# myChip register map
Vendor: ARM Ltd.; Series: ARMCM3; File version: 1.2
CPU: CM3 r2p1, little endian, no MPU, no FPU, 3 interrupt priority bits
Registers are 32-bit, read-write, reset 0x0 unless marked. A register's access mark holds for its fields unless they carry their own. Offsets are from the block's base; [hi:lo] are bit positions; {n}, {i} and the like mark numbered series.

## TMR9
Base 0x40030000
Same registers: TMR10 0x40031000
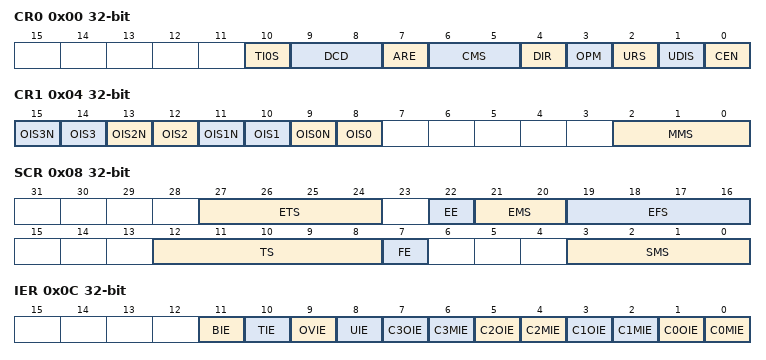
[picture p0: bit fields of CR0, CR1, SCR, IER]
0x00 CR0 — TMRx Control Register0
  [10] TI0S — TI0输入选择(TI0 Input Selection)
  [9:8] DCD — 时钟分频(Clock Division)
  [7] ARE — 自动重载使能(AutoReload Enable)
  [6:5] CMS — 中心对齐模式(Center-Aligned Mode Selection)
  [4] DIR — 计数方向(Counter Direction)
  [3] OPM — 单脉冲模式(One Pulse Mode)
  [2] URS — 更新事件源(Update Request Source)
  [1] UDIS — 更新禁止位(Update Disable)
  [0] CEN — 计数器使能位(Counter Enable):
0x04 CR1 — TMRx Control Register1
  [2n+9] OIS{n}N (n=0..3) — CH{n}N空闲状态输出电平(CH{n}N Output Idle-State):
  [2n+8] OIS{n} (n=0..3) — CH{n}空闲状态输出电平(CH{n} Output Idle-State):
  [2:0] MMS — 主模式选择(Master Mode Selection):
0x08 SCR — TMRx Slave Control Register
  [27:24] ETS — ETR输入源选择(ETR Input Shource Selection)
  [22] EE — ETR控制模式选择(ETR Mode Selection)
  [21:20] EMS — ETR边沿模式选择(ETR Edge-Mode Selection)
  [19:16] EFS — ETR滤波选择(ETR Filter Selection)
  [12:8] TS — 触发选择(Trigger Selection)
  [7] FE — 主从快速同步使能(Master/Slave Fast-Sync Enable)
  [3:0] SMS — 从模式选择(Slave Mode Selection):
0x0C IER — TMRx Interrupt Enable Register
  [11] BIE — 断路中断使能(Break Interrupt Enable)
  [10] TIE — 触发中断使能(Trigger Interrupt Enable)
  [9] OVIE — 计数上溢中断使能(Overflow Interrupt Enable)
  [8] UIE — 更新中断使能(Update Interrupt Enable)
  [2n+1] C{n}OIE (n=0..3) — CH{n}重复捕获中断使能(CH{n} OverCapture Interrupt Enable):
  [2n] C{n}MIE (n=0..3) — CH{n}比较中断使能(CH{n} Capture/Compare Interrupt Enable):
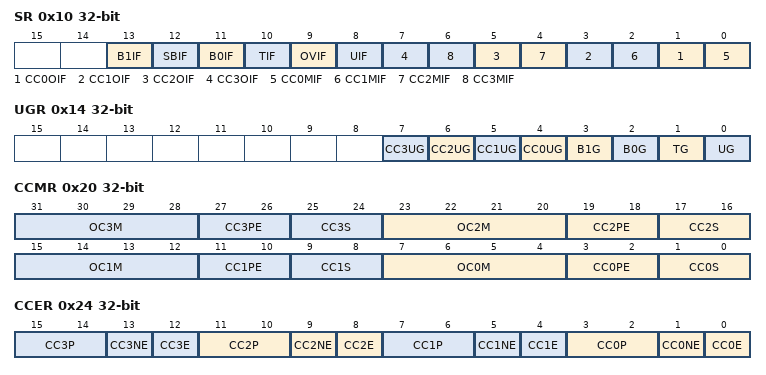
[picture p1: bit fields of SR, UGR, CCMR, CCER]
0x10 SR — TMRx Status Register
  [13] B1IF — 断路中断标志位(Break1 Interrupt Flag)
  [12] SBIF — 系统断路中断标志位(System Fault Break Interrupt Flag)
  [11] B0IF — 断路中断标志位(Break0 Interrupt Flag)
  [10] TIF — 触发中断标志(Trigger Interrupt Flag)
  [9] OVIF — 计数器上溢中断标志位(Counter Overflow Interrupt Flag)
  [8] UIF — 更新中断标志(Update Interrupt Flag)
  [2n+1] CC{n}OIF (n=0..3) — CC{n}重复捕获成功中断标志位(CC{n} OverCapture Interrupt Flag)
  [2n] CC{n}MIF (n=0..3) — CC{n}比较成功中断标志位(CC{n} Capture/Compare Interrupt Flag)
0x14 UGR — TMRx Update Generation Register
  [n+4] CC{n}UG (n=0..3) — CC{n}捕获/比较更新事件生成(CC{n} Capture/Compare Update Generation)
  [3] B1G — 断路1事件生成(Break1 Generation)
  [2] B0G — 断路0事件生成(Break0 Generation)
  [1] TG — 触发事件生成(Trigger Generation)
  [0] UG — 更新事件生成(Update Generation)
0x20 CCMR — TMRx Capture Compare Mode Register
  [8n+7:8n+4] OC{n}M (n=0..3) — CC{n}输入滤波/输出比较模式选择(CC{n} Input Filter/Output Compare Mode)
  [8n+3:8n+2] CC{n}PE (n=0..3) — CC{n}输入捕获分频/比较自动加载使能(CC{n} Compare Auto-Realod Enable)
  [8n+1:8n] CC{n}S (n=0..3) — CC{n}捕获/比较方向选择(CC{n} Capture Compare Selection)
0x24 CCER — TMRx Capture Compare Enable Register
  [4n+3:4n+2] CC{n}P (n=0..3) — CC{n}捕获/比较极性选择(CC{n} Compare/Capture Polarity)
  [4n+1] CC{n}NE (n=0..3) — CC{n}N捕获/比较互补通道使能(CC{n}N Capture/Compare Enable)
  [4n] CC{n}E (n=0..3) — CC{n}捕获/比较通道使能(CC{n} Capture/Compare Enable)
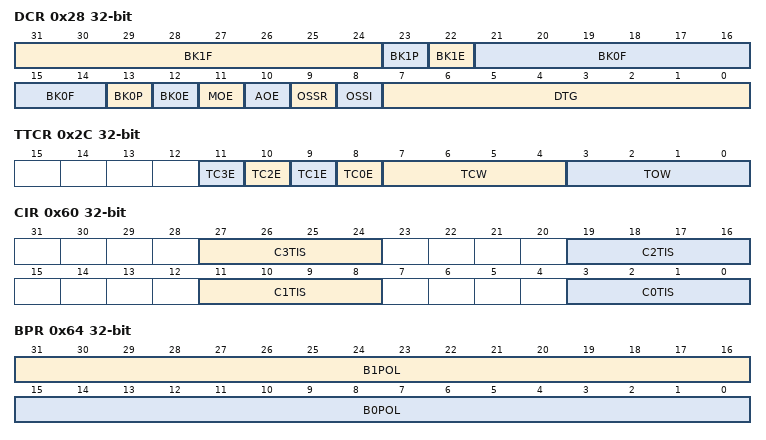
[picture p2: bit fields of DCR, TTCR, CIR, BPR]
0x28 DCR — TMRx Dead-Time Contorl Register
  [31:24] BK1F — 断路滤波器(Break1 Filter)
  [23] BK1P — 断路输入极性(Break1 Polarity)
  [22] BK1E — 断路控制使能(Break1 Enable)
  [21:14] BK0F — 断路滤波器(Break0 Filter)
  [13] BK0P — 断路输入极性(Break0 Polarity)
  [12] BK0E — 断路控制使能(Break0 Enable)
  [11] MOE — 主路输出使能(Main Output Enable)
  [10] AOE — 自动输出使能(Automatic Output Enable)
  [9] OSSR — 运行模式下关闭状态选择(Off-State Selection for Run-Mode)
  [8] OSSI — 空闲模式下关闭状态选择(Off-State Selection for Idle-Mode)
  [7:0] DTG — 配置死区时间选择(Dead-Time Generator Setup)
0x2C TTCR — TMRx Trigger Cycles Register
  [n+8] TC{n}E (n=0..3) — TRGO CH{n}输出使能(Trigger CH{n} Enable)
  [7:4] TCW — TRGCC脉冲宽度控制(Trigger Compare/Caputre Width)
  [3:0] TOW — TRGO脉冲宽度控制(Trigger Output Width)
0x30 CPR — TMRx Counter Period Register
  [15:0] CPV — 计数周期值(Counter Period Value)
0x38 PSCR — TMRx Prescaler Register
  [15:0] PSC — 预分频寄存器（Prescaler Value)
0x3C CNTR — TMRx Counter Register
  [15:0] CNT — 定时器计数值(Counter Value)
0x40 CRR — TMRx Counter Repeat Register
  [7:0] REP — 重复计数值(Counter Repeat Value)
{0x50+4i} CC{i}R (i=0..3) — TMRx Capture Compare Register{i}
  [15:0] CC{i}V — CC{i}捕获/比较值(CC{i} Capture/Compare Value)
0x60 CIR — TMRx Capture Input Register
  [27:24] C3TIS — CH3触发输入选择(CH3 Capture Input Selection)
  [19:16] C2TIS — CH2触发输入选择(CH2 Capture Input Selection)
  [11:8] C1TIS — CH1触发输入选择(CH1 Capture Input Selection)
  [3:0] C0TIS — CH0触发输入选择(CH0 Trigger Input Selection)
0x64 BPR — TMRx Break Polarity Register
  [31:16] B1POL — Break1输入极性选择(Break1 Input Polarity Selection)
  [15:0] B0POL — Break0输入极性选择(Break0 Input Polarity Selection)
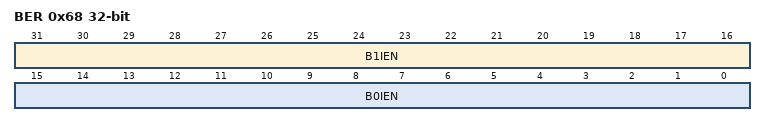
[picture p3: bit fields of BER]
0x68 BER — TMRx Break Enable Register
  [31:16] B1IEN — Break1输入使能控制(Break1 Input Enable)
  [15:0] B0IEN — Break0输入使能控制(Break0 Input Enable)
